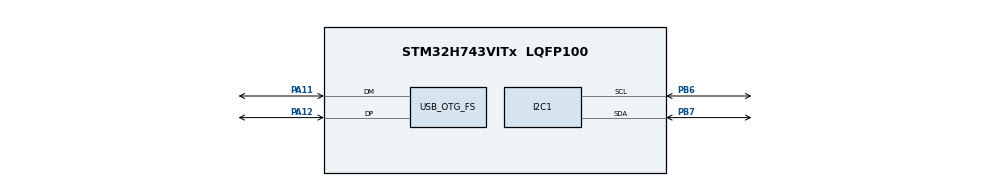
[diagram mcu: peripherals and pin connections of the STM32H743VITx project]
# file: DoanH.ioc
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CORTEX_M7.default_mode_Activation=1
I2C1.Timing=0x10C0ECFF
Mcu.Family=STM32H7
Mcu.Name=STM32H743VITx
Mcu.Package=LQFP100
NVIC.OTG_FS_IRQn=true\:0\:0\:false\:false\:true\:false\:true\:true
NVIC.PriorityGroup=NVIC_PRIORITYGROUP_4
PA11.Mode=Device_Only
PA11.Signal=USB_OTG_FS_DM
PA12.Mode=Device_Only
PA12.Signal=USB_OTG_FS_DP
PB6.Mode=I2C
PB6.Signal=I2C1_SCL
PB7.Mode=I2C
PB7.Signal=I2C1_SDA
PH0-OSC_IN\ (PH0).Mode=HSE-External-Oscillator
PH0-OSC_IN\ (PH0).Signal=RCC_OSC_IN
PH1-OSC_OUT\ (PH1).Mode=HSE-External-Oscillator
PH1-OSC_OUT\ (PH1).Signal=RCC_OSC_OUT
ProjectManager.HeapSize=0x400
ProjectManager.StackSize=0x800
ProjectManager.TargetToolchain=Makefile
RCC.ADCFreq_Value=50390625
RCC.APB1Freq_Value=100000000
RCC.APB2Freq_Value=100000000
RCC.APB3Freq_Value=100000000
RCC.APB4Freq_Value=100000000
RCC.CortexFreq_Value=400000000
RCC.D1PPRE=RCC_APB3_DIV2
RCC.D2PPRE1=RCC_APB1_DIV2
RCC.D2PPRE2=RCC_APB2_DIV2
RCC.D3PPRE=RCC_APB4_DIV2
RCC.DIVM1=5
RCC.DIVN1=160
RCC.HCLKFreq_Value=200000000
RCC.HPRE=RCC_HCLK_DIV2
RCC.PLLSourceVirtual=RCC_PLLSOURCE_HSE
RCC.SYSCLKFreq_VALUE=400000000
RCC.SYSCLKSource=RCC_SYSCLKSOURCE_PLLCLK
RCC.USBCLockSelection=RCC_USBCLKSOURCE_HSI48
RCC.USBFreq_Value=48000000
USB_DEVICE.CLASS_NAME_FS=CDC
USB_DEVICE.MANUFACTURER_STRING-CDC_FS=HungNguVL's_USB
USB_DEVICE.VID-CDC_FS=1000
USB_DEVICE.VirtualMode-CDC_FS=Cdc
USB_DEVICE.VirtualModeFS=Cdc_FS
USB_OTG_FS.VirtualMode=Device_Only
VP_MEMORYMAP_VS_MEMORYMAP.Mode=CurAppReg
VP_USB_DEVICE_VS_USB_DEVICE_CDC_FS.Mode=CDC_FS
board=custom

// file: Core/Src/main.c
/* USER CODE BEGIN Header */
/**
  ******************************************************************************
  * @file           : main.c
  * @brief          : Main program body
  ******************************************************************************
  * @attention
  *
  * Copyright (c) 2026 STMicroelectronics.
  * All rights reserved.
  *
  * This software is licensed under terms that can be found in the LICENSE file
  * in the root directory of this software component.
  * If no LICENSE file comes with this software, it is provided AS-IS.
  *
  ******************************************************************************
  */
/* USER CODE END Header */
#include "main.h"
#include "usb_device.h"
#include "mavlink_app.h"

I2C_HandleTypeDef hi2c1;

void SystemClock_Config(void);
static void MPU_Config(void);
static void MX_GPIO_Init(void);
static void MX_I2C1_Init(void);

int main(void)
{

  /* MPU Configuration--------------------------------------------------------*/
  MPU_Config();

  /* MCU Configuration--------------------------------------------------------*/

  /* Reset of all peripherals, Initializes the Flash interface and the Systick. */
  HAL_Init();

  /* Configure the system clock */
  SystemClock_Config();

  /* Initialize all configured peripherals */
  MX_GPIO_Init();
  MX_I2C1_Init();
  MX_USB_DEVICE_Init();
  /* MavlinkApp owns MPU init/calibration and USB MAVLink scheduling. Keep the
     board still for a short moment after boot so IMU bias calibration is valid. */
  MavlinkApp_Init(&hi2c1);

  /* Infinite loop */
  while (1)
  {

    /* USER CODE BEGIN 3 */
    /* Service MAVLink frequently. The function is non-blocking and internally
       rate-limits HEARTBEAT, ATTITUDE and debug messages. */
    MavlinkApp_Tick();
    HAL_Delay(5);
  }
  /* USER CODE END 3 */
}

void SystemClock_Config(void)
{
  RCC_OscInitTypeDef RCC_OscInitStruct = {0};
  RCC_ClkInitTypeDef RCC_ClkInitStruct = {0};

  /** Supply configuration update enable
  */
  HAL_PWREx_ConfigSupply(PWR_LDO_SUPPLY);

  /** Configure the main internal regulator output voltage
  */
  __HAL_PWR_VOLTAGESCALING_CONFIG(PWR_REGULATOR_VOLTAGE_SCALE1);

  while(!__HAL_PWR_GET_FLAG(PWR_FLAG_VOSRDY)) {}

  /** Initializes the RCC Oscillators according to the specified parameters
  * in the RCC_OscInitTypeDef structure.
  */
  RCC_OscInitStruct.OscillatorType = RCC_OSCILLATORTYPE_HSI48|RCC_OSCILLATORTYPE_HSE;
  RCC_OscInitStruct.HSEState = RCC_HSE_ON;
  RCC_OscInitStruct.HSI48State = RCC_HSI48_ON;
  RCC_OscInitStruct.PLL.PLLState = RCC_PLL_ON;
  RCC_OscInitStruct.PLL.PLLSource = RCC_PLLSOURCE_HSE;
  RCC_OscInitStruct.PLL.PLLM = 5;
  RCC_OscInitStruct.PLL.PLLN = 160;
  RCC_OscInitStruct.PLL.PLLP = 2;
  RCC_OscInitStruct.PLL.PLLQ = 2;
  RCC_OscInitStruct.PLL.PLLR = 2;
  RCC_OscInitStruct.PLL.PLLRGE = RCC_PLL1VCIRANGE_2;
  RCC_OscInitStruct.PLL.PLLVCOSEL = RCC_PLL1VCOWIDE;
  RCC_OscInitStruct.PLL.PLLFRACN = 0;
  if (HAL_RCC_OscConfig(&RCC_OscInitStruct) != HAL_OK)
  {
    Error_Handler();
  }

  /** Initializes the CPU, AHB and APB buses clocks
  */
  RCC_ClkInitStruct.ClockType = RCC_CLOCKTYPE_HCLK|RCC_CLOCKTYPE_SYSCLK
                              |RCC_CLOCKTYPE_PCLK1|RCC_CLOCKTYPE_PCLK2
                              |RCC_CLOCKTYPE_D3PCLK1|RCC_CLOCKTYPE_D1PCLK1;
  RCC_ClkInitStruct.SYSCLKSource = RCC_SYSCLKSOURCE_PLLCLK;
  RCC_ClkInitStruct.SYSCLKDivider = RCC_SYSCLK_DIV1;
  RCC_ClkInitStruct.AHBCLKDivider = RCC_HCLK_DIV2;
  RCC_ClkInitStruct.APB3CLKDivider = RCC_APB3_DIV2;
  RCC_ClkInitStruct.APB1CLKDivider = RCC_APB1_DIV2;
  RCC_ClkInitStruct.APB2CLKDivider = RCC_APB2_DIV2;
  RCC_ClkInitStruct.APB4CLKDivider = RCC_APB4_DIV2;

  if (HAL_RCC_ClockConfig(&RCC_ClkInitStruct, FLASH_LATENCY_2) != HAL_OK)
  {
    Error_Handler();
  }
}

static void MX_I2C1_Init(void)
{

  hi2c1.Instance = I2C1;
  hi2c1.Init.Timing = 0x10C0ECFF;
  hi2c1.Init.OwnAddress1 = 0;
  hi2c1.Init.AddressingMode = I2C_ADDRESSINGMODE_7BIT;
  hi2c1.Init.DualAddressMode = I2C_DUALADDRESS_DISABLE;
  hi2c1.Init.OwnAddress2 = 0;
  hi2c1.Init.OwnAddress2Masks = I2C_OA2_NOMASK;
  hi2c1.Init.GeneralCallMode = I2C_GENERALCALL_DISABLE;
  hi2c1.Init.NoStretchMode = I2C_NOSTRETCH_DISABLE;
  if (HAL_I2C_Init(&hi2c1) != HAL_OK)
  {
    Error_Handler();
  }

  /** Configure Analogue filter
  */
  if (HAL_I2CEx_ConfigAnalogFilter(&hi2c1, I2C_ANALOGFILTER_ENABLE) != HAL_OK)
  {
    Error_Handler();
  }

  /** Configure Digital filter
  */
  if (HAL_I2CEx_ConfigDigitalFilter(&hi2c1, 0) != HAL_OK)
  {
    Error_Handler();
  }

}

static void MX_GPIO_Init(void)
{

  /* GPIO Ports Clock Enable */
  __HAL_RCC_GPIOH_CLK_ENABLE();
  __HAL_RCC_GPIOA_CLK_ENABLE();
  __HAL_RCC_GPIOB_CLK_ENABLE();

}

 /* MPU Configuration */

void MPU_Config(void)
{
  MPU_Region_InitTypeDef MPU_InitStruct = {0};

  /* Disables the MPU */
  HAL_MPU_Disable();

  /** Initializes and configures the Region and the memory to be protected
  */
  MPU_InitStruct.Enable = MPU_REGION_ENABLE;
  MPU_InitStruct.Number = MPU_REGION_NUMBER0;
  MPU_InitStruct.BaseAddress = 0x0;
  MPU_InitStruct.Size = MPU_REGION_SIZE_4GB;
  MPU_InitStruct.SubRegionDisable = 0x87;
  MPU_InitStruct.TypeExtField = MPU_TEX_LEVEL0;
  MPU_InitStruct.AccessPermission = MPU_REGION_NO_ACCESS;
  MPU_InitStruct.DisableExec = MPU_INSTRUCTION_ACCESS_DISABLE;
  MPU_InitStruct.IsShareable = MPU_ACCESS_SHAREABLE;
  MPU_InitStruct.IsCacheable = MPU_ACCESS_NOT_CACHEABLE;
  MPU_InitStruct.IsBufferable = MPU_ACCESS_NOT_BUFFERABLE;

  HAL_MPU_ConfigRegion(&MPU_InitStruct);
  /* Enables the MPU */
  HAL_MPU_Enable(MPU_PRIVILEGED_DEFAULT);

}

void Error_Handler(void)
{
  __disable_irq();
  while (1)
  {
  }
}
